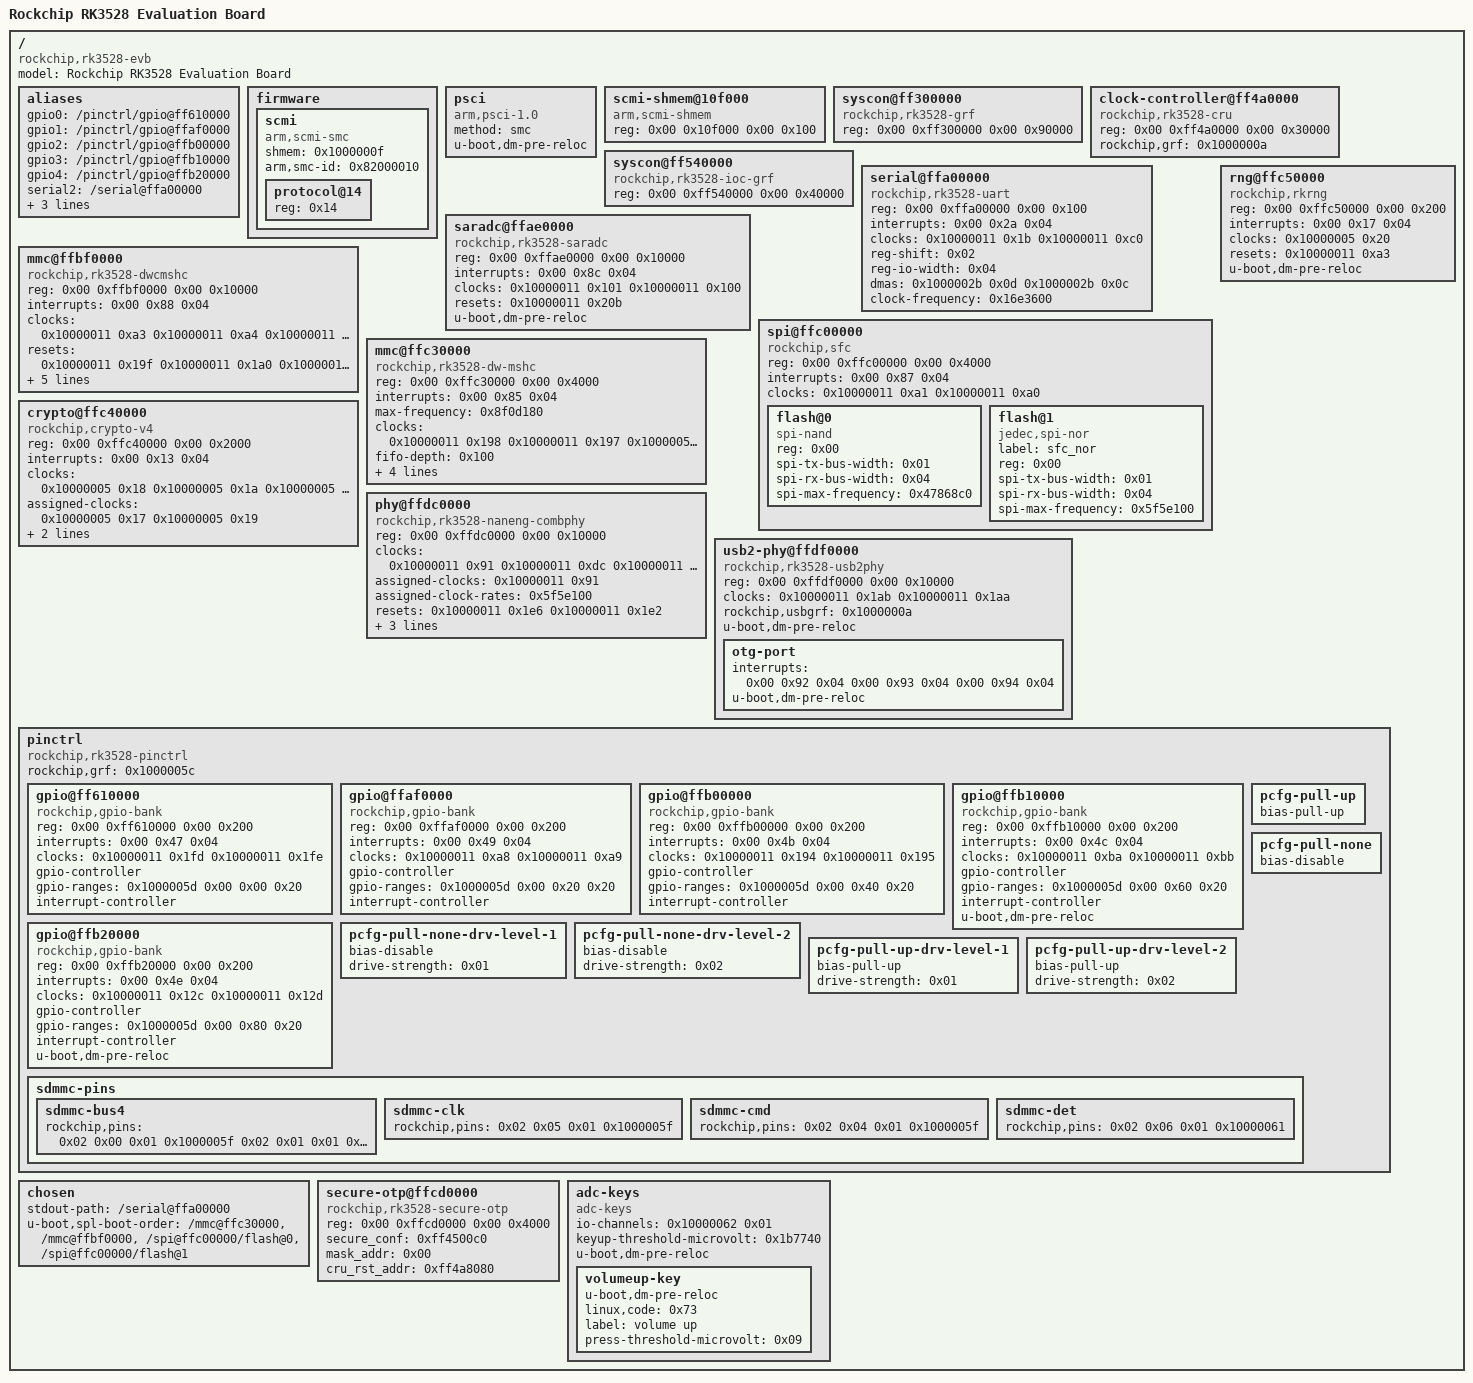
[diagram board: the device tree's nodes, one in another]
/dts-v1/;

/ {
	compatible = "rockchip,rk3528-evb", "rockchip,rk3528";
	#address-cells = <0x02>;
	#size-cells = <0x02>;
	model = "Rockchip RK3528 Evaluation Board";

	aliases {
		gpio0 = "/pinctrl/gpio@ff610000";
		gpio1 = "/pinctrl/gpio@ffaf0000";
		gpio2 = "/pinctrl/gpio@ffb00000";
		gpio3 = "/pinctrl/gpio@ffb10000";
		gpio4 = "/pinctrl/gpio@ffb20000";
		serial2 = "/serial@ffa00000";
		spi2 = "/spi@ffc00000";
		mmc0 = "/mmc@ffbf0000";
		mmc1 = "/mmc@ffc30000";
	};

	firmware {
		u-boot,dm-spl;

		scmi {
			compatible = "arm,scmi-smc";
			shmem = <0x1000000f>;
			arm,smc-id = <0x82000010>;
			#address-cells = <0x01>;
			#size-cells = <0x00>;
			u-boot,dm-spl;

			protocol@14 {
				reg = <0x14>;
				#clock-cells = <0x01>;
				u-boot,dm-spl;
				phandle = <0x10000005>;
			};
		};
	};

	psci {
		compatible = "arm,psci-1.0";
		method = "smc";
		u-boot,dm-pre-reloc;
		status = "okay";
	};

	scmi-shmem@10f000 {
		compatible = "arm,scmi-shmem";
		reg = <0x00 0x10f000 0x00 0x100>;
		u-boot,dm-spl;
		phandle = <0x1000000f>;
	};

	syscon@ff300000 {
		compatible = "rockchip,rk3528-grf", "syscon", "simple-mfd";
		reg = <0x00 0xff300000 0x00 0x90000>;
		u-boot,dm-spl;
		status = "okay";
		phandle = <0x1000000a>;
	};

	clock-controller@ff4a0000 {
		compatible = "rockchip,rk3528-cru";
		reg = <0x00 0xff4a0000 0x00 0x30000>;
		rockchip,grf = <0x1000000a>;
		#clock-cells = <0x01>;
		#reset-cells = <0x01>;
		u-boot,dm-spl;
		status = "okay";
		phandle = <0x10000011>;
	};

	syscon@ff540000 {
		compatible = "rockchip,rk3528-ioc-grf", "syscon";
		reg = <0x00 0xff540000 0x00 0x40000>;
		u-boot,dm-spl;
		status = "okay";
		phandle = <0x1000005c>;
	};

	serial@ffa00000 {
		compatible = "rockchip,rk3528-uart", "snps,dw-apb-uart";
		reg = <0x00 0xffa00000 0x00 0x100>;
		interrupts = <0x00 0x2a 0x04>;
		clocks = <0x10000011 0x1b 0x10000011 0xc0>;
		reg-shift = <0x02>;
		reg-io-width = <0x04>;
		dmas = <0x1000002b 0x0d 0x1000002b 0x0c>;
		status = "okay";
		clock-frequency = <0x16e3600>;
		u-boot,dm-spl;
	};

	saradc@ffae0000 {
		compatible = "rockchip,rk3528-saradc";
		reg = <0x00 0xffae0000 0x00 0x10000>;
		interrupts = <0x00 0x8c 0x04>;
		#io-channel-cells = <0x01>;
		clocks = <0x10000011 0x101 0x10000011 0x100>;
		resets = <0x10000011 0x20b>;
		reset-names = "saradc-apb";
		status = "okay";
		u-boot,dm-pre-reloc;
		phandle = <0x10000062>;
	};

	mmc@ffbf0000 {
		compatible = "rockchip,rk3528-dwcmshc";
		reg = <0x00 0xffbf0000 0x00 0x10000>;
		interrupts = <0x00 0x88 0x04>;
		clocks = <0x10000011 0xa3 0x10000011 0xa4 0x10000011 0xa5 0x10000011 0xa6 0x10000011 0xa7>;
		resets = <0x10000011 0x19f 0x10000011 0x1a0 0x10000011 0x1a1 0x10000011 0x1a2 0x10000011 0x1a3>;
		reset-names = "core", "bus", "axi", "block", "timer";
		max-frequency = <0xbebc200>;
		status = "okay";
		bus-width = <0x08>;
		u-boot,dm-spl;
		mmc-hs400-1_8v;
		mmc-hs400-enhanced-strobe;
		fixed-emmc-driver-type = <0x01>;
	};

	spi@ffc00000 {
		compatible = "rockchip,sfc";
		reg = <0x00 0xffc00000 0x00 0x4000>;
		interrupts = <0x00 0x87 0x04>;
		clocks = <0x10000011 0xa1 0x10000011 0xa0>;
		#address-cells = <0x01>;
		#size-cells = <0x00>;
		status = "okay";
		u-boot,dm-spl;

		flash@0 {
			u-boot,dm-spl;
			compatible = "spi-nand";
			reg = <0x00>;
			spi-tx-bus-width = <0x01>;
			spi-rx-bus-width = <0x04>;
			spi-max-frequency = <0x47868c0>;
		};

		flash@1 {
			u-boot,dm-spl;
			compatible = "jedec,spi-nor";
			label = "sfc_nor";
			reg = <0x00>;
			spi-tx-bus-width = <0x01>;
			spi-rx-bus-width = <0x04>;
			spi-max-frequency = <0x5f5e100>;
		};
	};

	mmc@ffc30000 {
		compatible = "rockchip,rk3528-dw-mshc", "rockchip,rk3288-dw-mshc";
		reg = <0x00 0xffc30000 0x00 0x4000>;
		interrupts = <0x00 0x85 0x04>;
		max-frequency = <0x8f0d180>;
		clocks = <0x10000011 0x198 0x10000011 0x197 0x10000056 0x01 0x10000056 0x02>;
		fifo-depth = <0x100>;
		resets = <0x10000011 0x2a9>;
		reset-names = "reset";
		rockchip,use-v2-tuning;
		pinctrl-names = "default";
		pinctrl-0 = <0x10000057 0x10000058 0x10000059 0x1000005a>;
		status = "okay";
		u-boot,dm-spl;
	};

	crypto@ffc40000 {
		compatible = "rockchip,crypto-v4";
		reg = <0x00 0xffc40000 0x00 0x2000>;
		interrupts = <0x00 0x13 0x04>;
		clocks = <0x10000005 0x18 0x10000005 0x1a 0x10000005 0x17 0x10000005 0x19>;
		assigned-clocks = <0x10000005 0x17 0x10000005 0x19>;
		assigned-clock-rates = <0x11e1a300 0x11e1a300>;
		resets = <0x10000011 0x3a>;
		reset-names = "crypto-rst";
		status = "okay";
		u-boot,dm-spl;
	};

	rng@ffc50000 {
		compatible = "rockchip,rkrng";
		reg = <0x00 0xffc50000 0x00 0x200>;
		interrupts = <0x00 0x17 0x04>;
		clocks = <0x10000005 0x20>;
		resets = <0x10000011 0xa3>;
		reset-names = "reset";
		status = "okay";
		u-boot,dm-pre-reloc;
	};

	phy@ffdc0000 {
		compatible = "rockchip,rk3528-naneng-combphy";
		reg = <0x00 0xffdc0000 0x00 0x10000>;
		#phy-cells = <0x01>;
		clocks = <0x10000011 0x91 0x10000011 0xdc 0x10000011 0xdd>;
		assigned-clocks = <0x10000011 0x91>;
		assigned-clock-rates = <0x5f5e100>;
		resets = <0x10000011 0x1e6 0x10000011 0x1e2>;
		reset-names = "combphy-apb", "combphy";
		rockchip,pipe-grf = <0x1000000a>;
		rockchip,pipe-phy-grf = <0x1000000a>;
		status = "okay";
		u-boot,dm-pre-reloc;
		phandle = <0x10000013>;
	};

	usb2-phy@ffdf0000 {
		compatible = "rockchip,rk3528-usb2phy";
		reg = <0x00 0xffdf0000 0x00 0x10000>;
		clocks = <0x10000011 0x1ab 0x10000011 0x1aa>;
		#clock-cells = <0x00>;
		rockchip,usbgrf = <0x1000000a>;
		status = "okay";
		u-boot,dm-pre-reloc;
		phandle = <0x10000015>;

		otg-port {
			#phy-cells = <0x00>;
			interrupts = <0x00 0x92 0x04 0x00 0x93 0x04 0x00 0x94 0x04>;
			interrupt-names = "otg-bvalid", "otg-id", "linestate";
			status = "okay";
			u-boot,dm-pre-reloc;
			phandle = <0x10000014>;
		};
	};

	pinctrl {
		compatible = "rockchip,rk3528-pinctrl";
		rockchip,grf = <0x1000005c>;
		#address-cells = <0x02>;
		#size-cells = <0x02>;
		ranges;
		u-boot,dm-spl;
		status = "okay";
		phandle = <0x1000005d>;

		gpio@ff610000 {
			compatible = "rockchip,gpio-bank";
			reg = <0x00 0xff610000 0x00 0x200>;
			interrupts = <0x00 0x47 0x04>;
			clocks = <0x10000011 0x1fd 0x10000011 0x1fe>;
			gpio-controller;
			#gpio-cells = <0x02>;
			gpio-ranges = <0x1000005d 0x00 0x00 0x20>;
			interrupt-controller;
			#interrupt-cells = <0x02>;
			u-boot,dm-spl;
			phandle = <0x10000029>;
		};

		gpio@ffaf0000 {
			compatible = "rockchip,gpio-bank";
			reg = <0x00 0xffaf0000 0x00 0x200>;
			interrupts = <0x00 0x49 0x04>;
			clocks = <0x10000011 0xa8 0x10000011 0xa9>;
			gpio-controller;
			#gpio-cells = <0x02>;
			gpio-ranges = <0x1000005d 0x00 0x20 0x20>;
			interrupt-controller;
			#interrupt-cells = <0x02>;
			u-boot,dm-spl;
		};

		gpio@ffb00000 {
			compatible = "rockchip,gpio-bank";
			reg = <0x00 0xffb00000 0x00 0x200>;
			interrupts = <0x00 0x4b 0x04>;
			clocks = <0x10000011 0x194 0x10000011 0x195>;
			gpio-controller;
			#gpio-cells = <0x02>;
			gpio-ranges = <0x1000005d 0x00 0x40 0x20>;
			interrupt-controller;
			#interrupt-cells = <0x02>;
			u-boot,dm-spl;
		};

		gpio@ffb10000 {
			compatible = "rockchip,gpio-bank";
			reg = <0x00 0xffb10000 0x00 0x200>;
			interrupts = <0x00 0x4c 0x04>;
			clocks = <0x10000011 0xba 0x10000011 0xbb>;
			gpio-controller;
			#gpio-cells = <0x02>;
			gpio-ranges = <0x1000005d 0x00 0x60 0x20>;
			interrupt-controller;
			#interrupt-cells = <0x02>;
			u-boot,dm-pre-reloc;
		};

		gpio@ffb20000 {
			compatible = "rockchip,gpio-bank";
			reg = <0x00 0xffb20000 0x00 0x200>;
			interrupts = <0x00 0x4e 0x04>;
			clocks = <0x10000011 0x12c 0x10000011 0x12d>;
			gpio-controller;
			#gpio-cells = <0x02>;
			gpio-ranges = <0x1000005d 0x00 0x80 0x20>;
			interrupt-controller;
			#interrupt-cells = <0x02>;
			u-boot,dm-pre-reloc;
		};

		pcfg-pull-up {
			bias-pull-up;
			u-boot,dm-spl;
			phandle = <0x10000061>;
		};

		pcfg-pull-none {
			bias-disable;
			u-boot,dm-spl;
			phandle = <0x1000005e>;
		};

		pcfg-pull-none-drv-level-1 {
			bias-disable;
			drive-strength = <0x01>;
			u-boot,dm-spl;
		};

		pcfg-pull-none-drv-level-2 {
			bias-disable;
			drive-strength = <0x02>;
			u-boot,dm-spl;
		};

		pcfg-pull-up-drv-level-1 {
			bias-pull-up;
			drive-strength = <0x01>;
			u-boot,dm-spl;
		};

		pcfg-pull-up-drv-level-2 {
			bias-pull-up;
			drive-strength = <0x02>;
			u-boot,dm-spl;
			phandle = <0x1000005f>;
		};

		sdmmc-pins {
			u-boot,dm-spl;

			sdmmc-bus4 {
				rockchip,pins = <0x02 0x00 0x01 0x1000005f 0x02 0x01 0x01 0x1000005f 0x02 0x02 0x01 0x1000005f 0x02 0x03 0x01 0x1000005f>;
				u-boot,dm-spl;
				phandle = <0x1000005a>;
			};

			sdmmc-clk {
				rockchip,pins = <0x02 0x05 0x01 0x1000005f>;
				u-boot,dm-spl;
				phandle = <0x10000057>;
			};

			sdmmc-cmd {
				rockchip,pins = <0x02 0x04 0x01 0x1000005f>;
				u-boot,dm-spl;
				phandle = <0x10000058>;
			};

			sdmmc-det {
				rockchip,pins = <0x02 0x06 0x01 0x10000061>;
				u-boot,dm-spl;
				phandle = <0x10000059>;
			};
		};
	};

	chosen {
		stdout-path = "/serial@ffa00000";
		u-boot,spl-boot-order = "/mmc@ffc30000", "/mmc@ffbf0000", "/spi@ffc00000/flash@0", "/spi@ffc00000/flash@1";
	};

	secure-otp@ffcd0000 {
		compatible = "rockchip,rk3528-secure-otp";
		reg = <0x00 0xffcd0000 0x00 0x4000>;
		secure_conf = <0xff4500c0>;
		mask_addr = <0x00>;
		cru_rst_addr = <0xff4a8080>;
		u-boot,dm-spl;
		status = "okay";
	};

	adc-keys {
		compatible = "adc-keys";
		io-channels = <0x10000062 0x01>;
		io-channel-names = "buttons";
		keyup-threshold-microvolt = <0x1b7740>;
		u-boot,dm-pre-reloc;
		status = "okay";

		volumeup-key {
			u-boot,dm-pre-reloc;
			linux,code = <0x73>;
			label = "volume up";
			press-threshold-microvolt = <0x09>;
		};
	};
};
